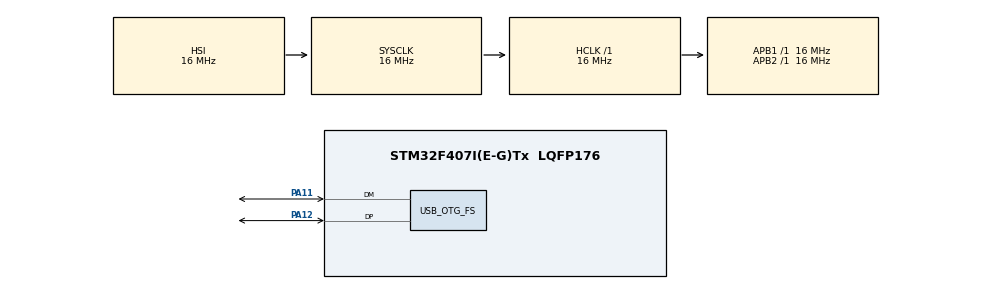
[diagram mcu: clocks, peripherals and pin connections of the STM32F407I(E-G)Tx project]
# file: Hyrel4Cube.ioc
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Mcu.Family=STM32F4
Mcu.Name=STM32F407I(E-G)Tx
Mcu.Package=LQFP176
NVIC.OTG_FS_IRQn=true\:0\:0\:false\:false\:true\:false\:true\:true
NVIC.PriorityGroup=NVIC_PRIORITYGROUP_4
PA11.Mode=Device_Only
PA11.Signal=USB_OTG_FS_DM
PA12.Mode=Device_Only
PA12.Signal=USB_OTG_FS_DP
PA13.Mode=Serial_Wire
PA13.Signal=SYS_JTMS-SWDIO
PA14.Mode=Serial_Wire
PA14.Signal=SYS_JTCK-SWCLK
PC14-OSC32_IN.Mode=LSE-External-Oscillator
PC14-OSC32_IN.Signal=RCC_OSC32_IN
PC15-OSC32_OUT.Mode=LSE-External-Oscillator
PC15-OSC32_OUT.Signal=RCC_OSC32_OUT
PH0-OSC_IN.Mode=HSE-External-Oscillator
PH0-OSC_IN.Signal=RCC_OSC_IN
PH1-OSC_OUT.Mode=HSE-External-Oscillator
PH1-OSC_OUT.Signal=RCC_OSC_OUT
ProjectManager.HeapSize=0x200
ProjectManager.StackSize=0x400
ProjectManager.TargetToolchain=STM32CubeIDE
RCC.AHBFreq_Value=16000000
RCC.APB1Freq_Value=16000000
RCC.APB2Freq_Value=16000000
RCC.CortexFreq_Value=16000000
RCC.HSE_VALUE=25000000
RCC.HSI_VALUE=16000000
RCC.PLLSourceVirtualString=RCC_PLLSOURCE_HSI
RCC.SYSCLKFreq_VALUE=16000000
RCC.VCOOutputFreq_Value=192000000
USB_DEVICE.CLASS_NAME_FS=CDC
USB_DEVICE.VirtualMode-CDC_FS=Cdc
USB_DEVICE.VirtualModeFS=Cdc_FS
USB_OTG_FS.VirtualMode=Device_Only
VP_USB_DEVICE_VS_USB_DEVICE_CDC_FS.Mode=CDC_FS
board=custom

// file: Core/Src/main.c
/* USER CODE BEGIN Header */
/**
  ******************************************************************************
  * @file           : main.c
  * @brief          : Main program body
  ******************************************************************************
  * @attention
  *
  * Copyright (c) 2022 STMicroelectronics.
  * All rights reserved.
  *
  * This software is licensed under terms that can be found in the LICENSE file
  * in the root directory of this software component.
  * If no LICENSE file comes with this software, it is provided AS-IS.
  *
  ******************************************************************************
  */
/* USER CODE END Header */
#include "main.h"
#include "usb_device.h"

/* USER CODE BEGIN Includes */
#include "misc_4xx.h"
#include "mailbox.h"
#include "HardwareInit.h"
/* USER CODE END Includes */

/* USER CODE BEGIN PM */
extern void initKey(boolean, char *, char *);

#ifdef HYDRA_DIAGS
#include "diags.h"
#endif

/* USER CODE END PM */

void SystemClock_Config(void);
static void MX_GPIO_Init(void);

/* USER CODE BEGIN 0 */
extern systemInfoStruct *_sysInfoPtr;
/* USER CODE END 0 */

int main(void)
{
  /* USER CODE BEGIN 1 */
#ifdef GB_DEBUGGING
	setupDBGMCU();    // set controls for debugger to keep peripherals from continuing to operate when paused.
#endif //GB_DEBUGGING
  /* USER CODE END 1 */

  /* MCU Configuration--------------------------------------------------------*/

  /* Reset of all peripherals, Initializes the Flash interface and the Systick. */
  HAL_Init();

  /* Configure the system clock */
  SystemClock_Config();

  /* USER CODE BEGIN SysInit */
  masterCommPort = BOOTUP;
  ExecutionPtr = &cmdQue[0];
  NVIC_SetVectorTable(NVIC_VectTab_FLASH, NVIC_VECTOR_OFFSET); // Set interrupt jump table location
  NVIC_PriorityGroupConfig(NVIC_PriorityGroup_4);              //4 bits for preemp priority 0 bit for sub priority
  InitGPIO();                 //configure direction and purpose of the I/O pin
  /* USER CODE END SysInit */

  /* Initialize all configured peripherals */
  //MX_GPIO_Init();
  MX_USB_DEVICE_Init();
  /* USER CODE BEGIN 2 */
#ifdef GB_HIDDEN_WARNINGS
	int doWeWantToReinstateClockInitCheck;
	//  if (ClocksFailedToInitialize)
	//  {
	//      setupIWDG(25.0f);  // enable SLOW IWDG timer (needs interrupts for LSI calib)
	//      pinSet(ERROR_LED);
	//  }
	//  else
	//  {
	//      setupIWDG(5.0f);  // enable IWDG timer (needs interrupts for LSI calib)
	//      pinClear(ERROR_LED);
	//  }
#endif //GB_HIDDEN_WARNINGS

	wiggleDebugIO(1);

	initAllHss();
	InitGlobals();              //initialize/clear CAN and MCODE globals
	DeInitLaser();
	InitializeMotorParameters();
	initMailbox();
	initKey(FALSE, _sysInfoPtr->lastKeyUsed, &GCodeArgComment[1]);     // must be after initMailbox; 	// tell the key checker where to put and find data
	InitTimer7();
	InitTimer3ForDelays();  // for delayMsec; delayuSec; delaySec   delayMs(

	//if (ClocksFailedToInitialize)
	{
		_heartbeatRateControl = HEARTBEAT_MODE_ABORT;
	}
	__disable_irq();            //prevent any interrupts until everything is initialized

	wiggleDebugIO(0);

	InitAllUARTS(SYSTEM_BAUD_RATE);

	CAN_Config(CAN1);
#ifdef USE_CAN2
	CAN_Config(CAN2);
#endif
	InitializeFixtureOffsets();

	ResetProcess(0);
	processSoapstringCommands=TRUE; // get ready to self initialize

	RCC_ClearFlag(); // clear flags indicating boot reason

	executeAnySpecialDebugStartCode();	//this call must remain here

	_heartbeatRateControl = HEARTBEAT_MODE_NORMAL;
	SysTick_Config(SystemCoreClock / SYSTICKS_PER_SECOND);//slice timer has lowest interrupt priority
	__enable_irq();  // now everything is ready, so let interrupts occur

#ifdef ADD_ON_SPI_DISPLAY
	display_Init();                     // do after SysTick started
#endif //ADD_ON_SPI_DISPLAY

#ifdef USE_AB_ENCODER
	timerInitEncoderAB(FALSE);  		// setup for GUI use
#endif //USE_AB_ENCODER
  /* USER CODE END 2 */

  /* Infinite loop */
  while (1)
  {

    /* USER CODE BEGIN 3 */

#ifdef ADD_ON_SPI_DISPLAY
#if 0 //NUKE
		if (GUI_GetCurrPage() != GUI_GetNextPage())
		{   // request to change page
			GUI_DrawPage(GUI_GetNextPage());
		}
		else if (_gs._display.updateIntervalCountMs >= _gs._display.updateIntervalMs)
		{
			_gs._display.updateIntervalCountMs = 0;
			GUI_RefreshPage(GUI_GetCurrPage());
		}
#else //!0
		if (_gs._displayIsAlive)
		{
			//			if (_gs._initializationComplete)
			//			{       // do want to overwrite the bootup display info
			GUI_ProcessCommandsFromQueue(10);       // process up to 10 gui cmds from the canbus

			if (GUI_GetCurrPage() != GUI_GetNextPage())
			{       // keep page change in the foreground
				_gs._displayForceRedraw = FALSE;
				GUI_DrawPage(GUI_GetNextPage());

			}
			else if (_gs._displayForceRedraw)
			{
				_gs._displayForceRedraw = FALSE;
				GUI_RedrawCurrentPage();
			}
			else if (GUI_RefreshIntervalReached())
			{
				GUI_DrawJustDynamicValues();
			}
			else
			{
				GUI_DrawFakeLeds(FALSE);
			}
			//			}
			//			else
			//			{
			//				displayBootSequence();
			//			}
		}
#endif //!0
#endif //ADD_ON_SPI_DISPLAY
  }
  /* USER CODE END 3 */
}

void SystemClock_Config(void)
{
  RCC_OscInitTypeDef RCC_OscInitStruct = {0};
  RCC_ClkInitTypeDef RCC_ClkInitStruct = {0};

  /** Configure the main internal regulator output voltage
  */
  __HAL_RCC_PWR_CLK_ENABLE();
  __HAL_PWR_VOLTAGESCALING_CONFIG(PWR_REGULATOR_VOLTAGE_SCALE1);

  /** Initializes the RCC Oscillators according to the specified parameters
  * in the RCC_OscInitTypeDef structure.
  */
  RCC_OscInitStruct.OscillatorType = RCC_OSCILLATORTYPE_HSI;
  RCC_OscInitStruct.HSIState = RCC_HSI_ON;
  RCC_OscInitStruct.HSICalibrationValue = RCC_HSICALIBRATION_DEFAULT;
  RCC_OscInitStruct.PLL.PLLState = RCC_PLL_ON;
  RCC_OscInitStruct.PLL.PLLSource = RCC_PLLSOURCE_HSI;
  RCC_OscInitStruct.PLL.PLLM = 16;
  RCC_OscInitStruct.PLL.PLLN = 192;
  RCC_OscInitStruct.PLL.PLLP = RCC_PLLP_DIV2;
  RCC_OscInitStruct.PLL.PLLQ = 4;
  if (HAL_RCC_OscConfig(&RCC_OscInitStruct) != HAL_OK)
  {
    Error_Handler();
  }

  /** Initializes the CPU, AHB and APB buses clocks
  */
  RCC_ClkInitStruct.ClockType = RCC_CLOCKTYPE_HCLK|RCC_CLOCKTYPE_SYSCLK
                              |RCC_CLOCKTYPE_PCLK1|RCC_CLOCKTYPE_PCLK2;
  RCC_ClkInitStruct.SYSCLKSource = RCC_SYSCLKSOURCE_HSI;
  RCC_ClkInitStruct.AHBCLKDivider = RCC_SYSCLK_DIV1;
  RCC_ClkInitStruct.APB1CLKDivider = RCC_HCLK_DIV1;
  RCC_ClkInitStruct.APB2CLKDivider = RCC_HCLK_DIV1;

  if (HAL_RCC_ClockConfig(&RCC_ClkInitStruct, 0x00000000U) != HAL_OK) //FLASH_LATENCY_0
  {
    Error_Handler();
  }
}

static void MX_GPIO_Init(void)
{

  /* GPIO Ports Clock Enable */
  __HAL_RCC_GPIOC_CLK_ENABLE();
  __HAL_RCC_GPIOH_CLK_ENABLE();
  __HAL_RCC_GPIOA_CLK_ENABLE();

}

void Error_Handler(void)
{
  __disable_irq();
  while (1)
  {
  }
}
